# STM32U5A9xx register map
File version: 1.0
Registers are 32-bit, read-write, reset 0x0 unless marked. A register's access mark holds for its fields unless they carry their own. Offsets are from the block's base; [hi:lo] are bit positions; {n}, {i} and the like mark numbered series.

## GFXMMU — GFXMMU registers
Base 0x4002C000
Same registers: GFXMMU_S 0x5002C000
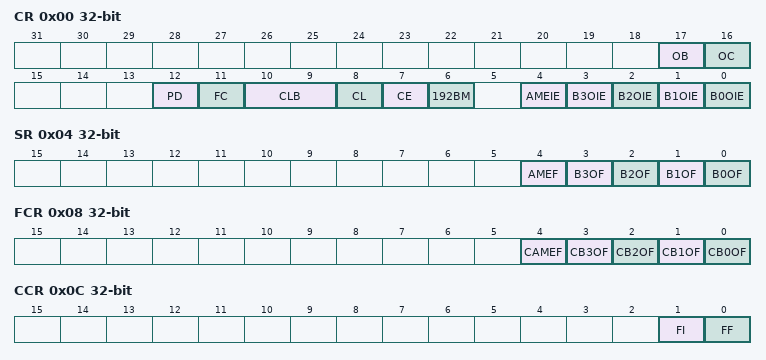
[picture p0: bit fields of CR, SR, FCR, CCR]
0x00 CR — GFXMMU configuration register
  [17] OB — Outer Bufferability
  [16] OC — Outer Cachability
  [12] PD — Prefetch Disable
  [11] FC — Force Caching
  [10:9] CLB — CLB[1:0]: Cache Lock Buffer
  [8] CL — Cache Lock
  [7] CE — Cache Enable
  [6] 192BM — 192 block mode
  [4] AMEIE — AHB master error interrupt enable
  [n] B{n}OIE (n=0..3) — Buffer {n} overflow interrupt enable
0x04 SR — GFXMMU status register
  [4] AMEF — AHB master error flag
  [n] B{n}OF (n=0..3) — Buffer {n} overflow flag
0x08 FCR — GFXMMU flag clear register
  [4] CAMEF — Clear AHB master error flag
  [n] CB{n}OF (n=0..3) — Clear buffer {n} overflow flag
0x0C CCR — GFXMMU Cache Control Register
  [1] FI — Clear buffer 1 overflow flag
  [0] FF — Clear buffer 0 overflow flag
0x10 DVR — GFXMMU default value register
  [31:0] DV — DV[31:0] bits (Default value)
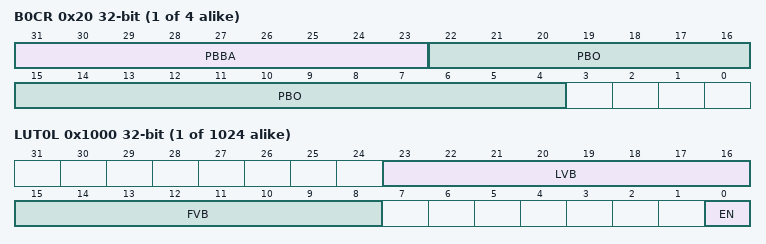
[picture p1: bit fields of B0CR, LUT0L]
{0x20+4i} B{i}CR (i=0..3) — GFXMMU buffer {i} configuration register
  [31:23] PBBA — PBBA[31:23] bits (Physical buffer base address)
  [22:4] PBO — PB0[22:4] bits (Physical buffer offset)
0xFF0 HWCFGR — GFXMMU hardware configuration register
0xFF4 VERR — GFXMMU version register
0xFF8 IPIDR — GFXMMU identification register
0xFFC SIDR — GFXMMU size identification register
{0x1000+8i} LUT{i}L (i=0..1023) — GFXMMU LUT registers
  [23:16] LVB — LVB[7:0] bits (Last visible block)
  [15:8] FVB — FVB[7:0] bits (First visible block)
  [0] EN — Enable
{0x1004+8i} LUT{i}H (i=0..1023) — GFXMMU LUT registers
  [21:4] LO — LO[21:4] bits (Line offset)

## ICACHE — Instruction Cache
Base 0x40030400
Same registers: ICACHE_S 0x50030400
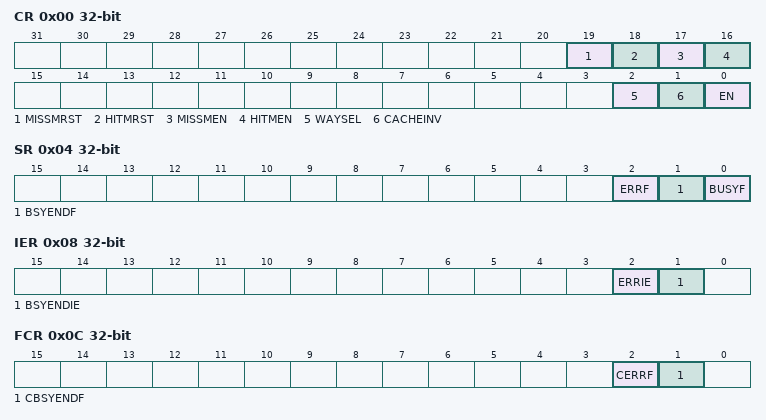
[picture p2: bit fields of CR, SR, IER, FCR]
0x00 CR — ICACHE control register
  [19] MISSMRST — Miss monitor reset
  [18] HITMRST — Hit monitor reset
  [17] MISSMEN — Miss monitor enable
  [16] HITMEN — Hit monitor enable
  [2] WAYSEL — Ways selection
    0=ICACHE_1WAY (1-way cache (direct mapped cache)); 1=ICACHE_2WAYS (2-ways set associative cache (default))
  [1] CACHEINV — Cache invalidation
  [0] EN — Enable
0x04 SR — ICACHE status register
  [2] ERRF — Cache error flag
  [1] BSYENDF — Busy end flag
  [0] BUSYF — Busy flag
0x08 IER — ICACHE interrupt enable register
  [2] ERRIE — Cache error interrupt enable
  [1] BSYENDIE — Busy end interrupt enable
0x0C FCR — ICACHE Flag clear register
  [2] CERRF — Cache error flag clear
  [1] CBSYENDF — Busy end flag clear
0x10 HMONR — ICACHE hit monitor register
  [31:0] HITMON — Cache hit monitor register
0x14 MMONR — ICACHE miss monitor register
  [15:0] MISSMON — Cache miss monitor register
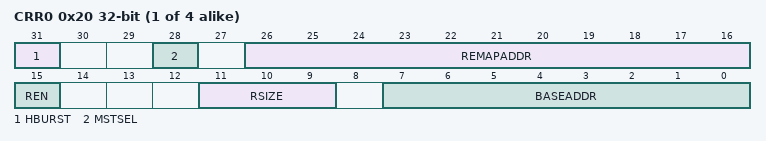
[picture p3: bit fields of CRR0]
{0x20+4i} CRR{i} (i=0..3) — ICACHE region {i} configuration register
  [31] HBURST — Region X output burst type
  [28] MSTSEL — Region X AHB cache master selection
  [26:16] REMAPADDR — Remap address of Region X to be remapped
  [15] REN — Region X enable
  [11:9] RSIZE — Region X size
  [7:0] BASEADDR — Base address of region X to remap

## DCACHE1 — Data Cache
Base 0x40031400
Same registers: DCACHE2 0x40031800, DCACHE1_S 0x50031400, DCACHE2_S 0x50031800
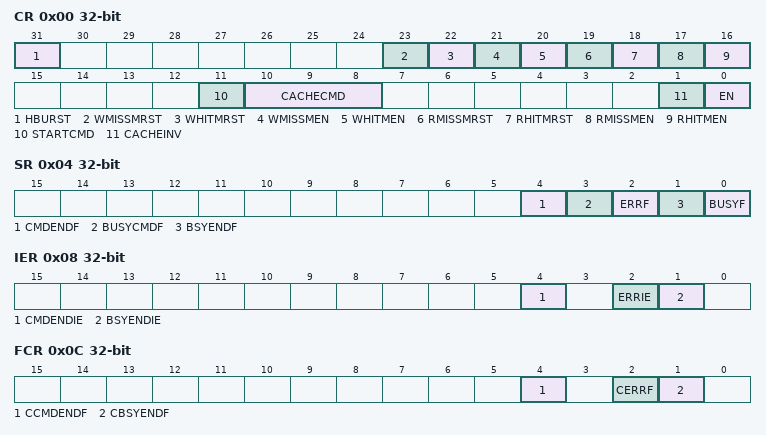
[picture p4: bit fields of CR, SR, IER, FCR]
0x00 CR — DCACHE control register
  [31] HBURST — Read burst type
    0=WRAP; 1=INCR
  [23] WMISSMRST — Write Miss monitor reset
  [22] WHITMRST — Write Hit monitor reset
  [21] WMISSMEN — Write Miss monitor enable
  [20] WHITMEN — Write Hit monitor enable
  [19] RMISSMRST — Read Miss monitor reset
  [18] RHITMRST — Read Hit monitor reset
  [17] RMISSMEN — Read Miss monitor enable
  [16] RHITMEN — Read Hit monitor enable
  [11] STARTCMD — Start command
  [10:8] CACHECMD — Cache command
    2=INVALIDATE_BY_ADDR; 1=CLEAN_BY_ADDR; 3=CLEAN_INVALIDATE_BY_ADDR; 0=NO_OPERATION
  [1] CACHEINV — Cache invalidation
  [0] EN — Enable
0x04 SR — DCACHE status register
  [4] CMDENDF — Command end flag
  [3] BUSYCMDF — Busy command flag
  [2] ERRF — Cache error flag
  [1] BSYENDF — Busy end flag
  [0] BUSYF — Busy flag
0x08 IER — DCACHE interrupt enable register
  [4] CMDENDIE — Command end interrupt enable
  [2] ERRIE — Cache error interrupt enable
  [1] BSYENDIE — Busy end interrupt enable
0x0C FCR — DCACHE Flag clear register
  [4] CCMDENDF — Command end flag clear
  [2] CERRF — Cache error flag clear
  [1] CBSYENDF — Busy end flag clear
0x10 RHMONR — DCACHE Read hit monitor register
  [31:0] RHITMON — Cache Read hit monitor register
0x14 RMMONR — DCACHE Read miss monitor register
  [15:0] RMISSMON — Cache Read miss monitor register
0x20 WHMONR — DCACHE Write hit monitor register
  [31:0] WHITMON — Cache Read hit monitor register
0x24 WMMONR — DCACHE Write miss monitor register
  [15:0] WMISSMON — Cache Read miss monitor register
0x28 CMDRSADDRR — DCACHE Command Start Address register
  [31:5] CMDSTARTADDR — Command start address
0x2C CMDREADDRR — DCACHE Command End Address register
  [31:5] CMDENDADDR — Command end address
